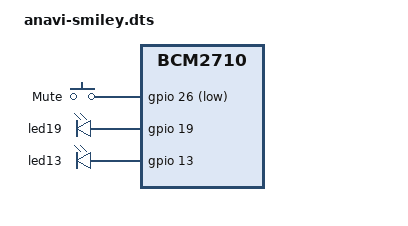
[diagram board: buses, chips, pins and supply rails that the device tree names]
/dts-v1/;
/plugin/;
/ {
	compatible = "brcm,bcm2835", "brcm,bcm2708", "brcm,bcm2709", "brcm,bcm2710";

	fragment@0 {
		target-path = "/";
		__overlay__ {
			keypad: anavi-smiley {
				compatible = "gpio-keys";
				autorepeat;
				button-26 {
					label = "Mute";
					linux,code = <113>;
					gpios = <&gpio 26 1>;
				};
			};
		};
	};

	fragment@1 {
		target = <&leds>;
		__overlay__ {
			hb_led: led-19 {
				label = "led19";
				linux,default-trigger = "heartbeat";
				gpios = <&gpio 19 0>;
         		};
			cpu_led: led-13 {
				label = "led13";
				linux,default-trigger = "cpu0";
				gpios = <&gpio 13 0>;
			};
      		};
   	};
 
};
